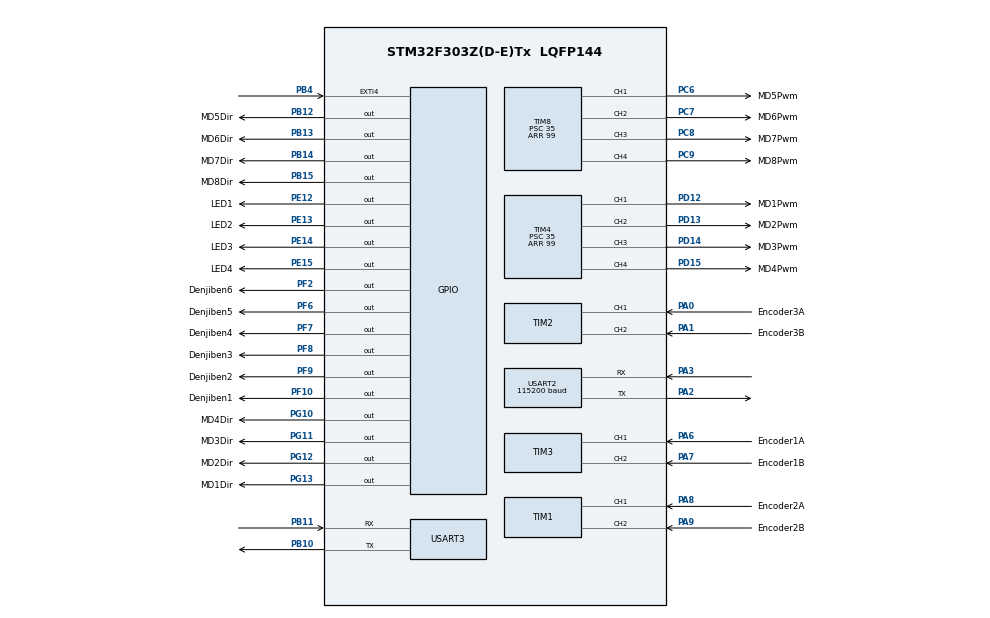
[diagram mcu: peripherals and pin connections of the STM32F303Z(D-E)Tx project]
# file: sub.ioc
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Mcu.Family=STM32F3
Mcu.Name=STM32F303Z(D-E)Tx
Mcu.Package=LQFP144
NVIC.PriorityGroup=NVIC_PRIORITYGROUP_4
NVIC.USART2_IRQn=true\:0\:0\:false\:false\:true\:true\:true\:true
NVIC.USART3_IRQn=true\:0\:0\:false\:false\:true\:true\:true\:true
PA0.GPIO_Label=Encoder3A
PA0.Signal=S_TIM2_CH1_ETR
PA1.GPIO_Label=Encoder3B
PA1.Signal=S_TIM2_CH2
PA2.Mode=Asynchronous
PA2.Signal=USART2_TX
PA3.Mode=Asynchronous
PA3.Signal=USART2_RX
PA6.GPIO_Label=Encoder1A
PA6.Signal=S_TIM3_CH1
PA7.GPIO_Label=Encoder1B
PA7.Signal=S_TIM3_CH2
PA8.GPIO_Label=Encoder2A
PA8.Signal=S_TIM1_CH1
PA9.GPIO_Label=Encoder2B
PA9.Signal=S_TIM1_CH2
PB10.Mode=Asynchronous
PB10.Signal=USART3_TX
PB11.Mode=Asynchronous
PB11.Signal=USART3_RX
PB12.GPIO_Label=MD5Dir
PB12.Signal=GPIO_Output
PB13.GPIO_Label=MD6Dir
PB13.Signal=GPIO_Output
PB14.GPIO_Label=MD7Dir
PB14.Signal=GPIO_Output
PB15.GPIO_Label=MD8Dir
PB15.Signal=GPIO_Output
PB4.Signal=GPXTI4
PC6.GPIO_Label=MD5Pwm
PC6.Signal=S_TIM8_CH1
PC7.GPIO_Label=MD6Pwm
PC7.Signal=S_TIM8_CH2
PC8.GPIO_Label=MD7Pwm
PC8.Signal=S_TIM8_CH3
PC9.GPIO_Label=MD8Pwm
PC9.Signal=S_TIM8_CH4
PD12.GPIO_Label=MD1Pwm
PD12.Signal=S_TIM4_CH1
PD13.GPIO_Label=MD2Pwm
PD13.Signal=S_TIM4_CH2
PD14.GPIO_Label=MD3Pwm
PD14.Signal=S_TIM4_CH3
PD15.GPIO_Label=MD4Pwm
PD15.Signal=S_TIM4_CH4
PE12.GPIO_Label=LED1
PE12.Signal=GPIO_Output
PE13.GPIO_Label=LED2
PE13.Signal=GPIO_Output
PE14.GPIO_Label=LED3
PE14.Signal=GPIO_Output
PE15.GPIO_Label=LED4
PE15.Signal=GPIO_Output
PF10.GPIO_Label=Denjiben1
PF10.Signal=GPIO_Output
PF2.GPIO_Label=Denjiben6
PF2.Signal=GPIO_Output
PF6.GPIO_Label=Denjiben5
PF6.Signal=GPIO_Output
PF7.GPIO_Label=Denjiben4
PF7.Signal=GPIO_Output
PF8.GPIO_Label=Denjiben3
PF8.Signal=GPIO_Output
PF9.GPIO_Label=Denjiben2
PF9.Signal=GPIO_Output
PG10.GPIO_Label=MD4Dir
PG10.Signal=GPIO_Output
PG11.GPIO_Label=MD3Dir
PG11.Signal=GPIO_Output
PG12.GPIO_Label=MD2Dir
PG12.Signal=GPIO_Output
PG13.GPIO_Label=MD1Dir
PG13.Signal=GPIO_Output
ProjectManager.HeapSize=0x200
ProjectManager.StackSize=0x400
ProjectManager.TargetToolchain=STM32CubeIDE
RCC.AHBFreq_Value=72000000
RCC.APB1CLKDivider=RCC_HCLK_DIV2
RCC.APB1Freq_Value=36000000
RCC.APB1TimFreq_Value=72000000
RCC.APB2Freq_Value=72000000
RCC.APB2TimFreq_Value=72000000
RCC.CortexFreq_Value=72000000
RCC.HCLKFreq_Value=72000000
RCC.HSE_VALUE=8000000
RCC.HSI_VALUE=8000000
RCC.LSE_VALUE=32768
RCC.PLLMUL=RCC_PLL_MUL9
RCC.SYSCLKFreq_VALUE=72000000
RCC.SYSCLKSourceVirtual=RCC_SYSCLKSOURCE_PLLCLK
RCC.USBFreq_Value=72000000
SH.S_TIM1_CH1.0=TIM1_CH1,Encoder_Interface
SH.S_TIM1_CH2.0=TIM1_CH2,Encoder_Interface
SH.S_TIM2_CH1_ETR.0=TIM2_CH1,Encoder_Interface
SH.S_TIM2_CH2.0=TIM2_CH2,Encoder_Interface
SH.S_TIM3_CH1.0=TIM3_CH1,Encoder_Interface
SH.S_TIM3_CH2.0=TIM3_CH2,Encoder_Interface
SH.S_TIM4_CH1.0=TIM4_CH1,PWM Generation1 CH1
SH.S_TIM4_CH2.0=TIM4_CH2,PWM Generation2 CH2
SH.S_TIM4_CH3.0=TIM4_CH3,PWM Generation3 CH3
SH.S_TIM4_CH4.0=TIM4_CH4,PWM Generation4 CH4
SH.S_TIM8_CH1.0=TIM8_CH1,PWM Generation1 CH1
SH.S_TIM8_CH2.0=TIM8_CH2,PWM Generation2 CH2
SH.S_TIM8_CH3.0=TIM8_CH3,PWM Generation3 CH3
SH.S_TIM8_CH4.0=TIM8_CH4,PWM Generation4 CH4
TIM4.AutoReloadPreload=TIM_AUTORELOAD_PRELOAD_ENABLE
TIM4.Channel-PWM\ Generation1\ CH1=TIM_CHANNEL_1
TIM4.Channel-PWM\ Generation2\ CH2=TIM_CHANNEL_2
TIM4.Channel-PWM\ Generation3\ CH3=TIM_CHANNEL_3
TIM4.Channel-PWM\ Generation4\ CH4=TIM_CHANNEL_4
TIM4.Period=99
TIM4.Prescaler=35
TIM8.AutoReloadPreload=TIM_AUTORELOAD_PRELOAD_ENABLE
TIM8.Channel-PWM\ Generation1\ CH1=TIM_CHANNEL_1
TIM8.Channel-PWM\ Generation2\ CH2=TIM_CHANNEL_2
TIM8.Channel-PWM\ Generation3\ CH3=TIM_CHANNEL_3
TIM8.Channel-PWM\ Generation4\ CH4=TIM_CHANNEL_4
TIM8.Period=99
TIM8.Prescaler=35
USART2.BaudRate=115200
USART2.Mode=MODE_RX
USART2.VirtualMode-Asynchronous=VM_ASYNC
USART3.VirtualMode-Asynchronous=VM_ASYNC
board=custom

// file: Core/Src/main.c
/* USER CODE BEGIN Header */
/**
  ******************************************************************************
  * @file           : main.c
  * @brief          : Main program body
  ******************************************************************************
  * @attention
  *
  * Copyright (c) 2024 STMicroelectronics.
  * All rights reserved.
  *
  * This software is licensed under terms that can be found in the LICENSE file
  * in the root directory of this software component.
  * If no LICENSE file comes with this software, it is provided AS-IS.
  *
  ******************************************************************************
  */
/* USER CODE END Header */
#include "main.h"
#include "tim.h"
#include "usart.h"
#include "gpio.h"

/* USER CODE BEGIN Includes */
#include <cxxmain.h>
/* USER CODE END Includes */

void SystemClock_Config(void);

int main(void)
{
  /* USER CODE BEGIN 1 */
    cxx_pre_init();
  /* USER CODE END 1 */

  /* MCU Configuration--------------------------------------------------------*/

  /* Reset of all peripherals, Initializes the Flash interface and the Systick. */
  LL_APB2_GRP1_EnableClock(LL_APB2_GRP1_PERIPH_SYSCFG);
  LL_APB1_GRP1_EnableClock(LL_APB1_GRP1_PERIPH_PWR);

  /* System interrupt init*/
  NVIC_SetPriorityGrouping(NVIC_PRIORITYGROUP_4);

  /* SysTick_IRQn interrupt configuration */
  NVIC_SetPriority(SysTick_IRQn, NVIC_EncodePriority(NVIC_GetPriorityGrouping(),15, 0));

  /* USER CODE BEGIN Init */
    cxx_init();
  /* USER CODE END Init */

  /* Configure the system clock */
  SystemClock_Config();

  /* USER CODE BEGIN SysInit */
    cxx_sysinit();
  /* USER CODE END SysInit */

  /* Initialize all configured peripherals */
  MX_GPIO_Init();
  MX_TIM1_Init();
  MX_TIM2_Init();
  MX_TIM3_Init();
  MX_TIM4_Init();
  MX_TIM8_Init();
  MX_USART2_UART_Init();
  MX_USART3_UART_Init();
  /* USER CODE BEGIN 2 */
    cxx_post_init();
  /* USER CODE END 2 */

  /* Infinite loop */
  while (1)
  {

    /* USER CODE BEGIN 3 */
    cxx_loop();
  }
  /* USER CODE END 3 */
}

void SystemClock_Config(void)
{
  LL_FLASH_SetLatency(LL_FLASH_LATENCY_2);
  while(LL_FLASH_GetLatency()!= LL_FLASH_LATENCY_2)
  {
  }
  LL_RCC_HSI_Enable();

   /* Wait till HSI is ready */
  while(LL_RCC_HSI_IsReady() != 1)
  {

  }
  LL_RCC_HSI_SetCalibTrimming(16);
  LL_RCC_PLL_ConfigDomain_SYS(LL_RCC_PLLSOURCE_HSI, LL_RCC_PLL_MUL_9, LL_RCC_PREDIV_DIV_1);
  LL_RCC_PLL_Enable();

   /* Wait till PLL is ready */
  while(LL_RCC_PLL_IsReady() != 1)
  {

  }
  LL_RCC_SetAHBPrescaler(LL_RCC_SYSCLK_DIV_1);
  LL_RCC_SetAPB1Prescaler(LL_RCC_APB1_DIV_2);
  LL_RCC_SetAPB2Prescaler(LL_RCC_APB2_DIV_1);
  LL_RCC_SetSysClkSource(LL_RCC_SYS_CLKSOURCE_PLL);

   /* Wait till System clock is ready */
  while(LL_RCC_GetSysClkSource() != LL_RCC_SYS_CLKSOURCE_STATUS_PLL)
  {

  }
  LL_Init1msTick(72000000);
  LL_SetSystemCoreClock(72000000);
  LL_RCC_SetUSARTClockSource(LL_RCC_USART2_CLKSOURCE_PCLK1);
  LL_RCC_SetUSARTClockSource(LL_RCC_USART3_CLKSOURCE_PCLK1);
  LL_RCC_SetTIMClockSource(LL_RCC_TIM1_CLKSOURCE_PCLK2);
  LL_RCC_SetTIMClockSource(LL_RCC_TIM8_CLKSOURCE_PCLK2);
  LL_RCC_SetTIMClockSource(LL_RCC_TIM2_CLKSOURCE_PCLK1);
  LL_RCC_SetTIMClockSource(LL_RCC_TIM34_CLKSOURCE_PCLK1);
}

void Error_Handler(void)
{
  __disable_irq();
  while (1)
  {
  }
}
